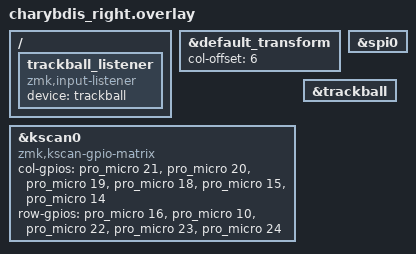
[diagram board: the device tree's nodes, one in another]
#include "charybdis.dtsi"
#include "charybdis_pmw3610.dtsi"

// The matrix transform is 6 columns over because the left half is 6 columns wide.
&default_transform {
	col-offset = <6>;
};

&kscan0 {
	compatible = "zmk,kscan-gpio-matrix";
	
	col-gpios
		= <&pro_micro 21 (GPIO_ACTIVE_HIGH | GPIO_PULL_DOWN)>//8
		, <&pro_micro 20 (GPIO_ACTIVE_HIGH | GPIO_PULL_DOWN)>//7
		, <&pro_micro 19 (GPIO_ACTIVE_HIGH | GPIO_PULL_DOWN)>//6
		, <&pro_micro 18 (GPIO_ACTIVE_HIGH | GPIO_PULL_DOWN)>//10
		, <&pro_micro 15 (GPIO_ACTIVE_HIGH | GPIO_PULL_DOWN)>//20
		, <&pro_micro 14 (GPIO_ACTIVE_HIGH | GPIO_PULL_DOWN)>//19
		;

	row-gpios
                = <&pro_micro 16  GPIO_ACTIVE_HIGH>//21
                , <&pro_micro 10  GPIO_ACTIVE_HIGH>//18
                , <&pro_micro 22  GPIO_ACTIVE_HIGH>//5
                , <&pro_micro 23  GPIO_ACTIVE_HIGH>//4
                , <&pro_micro 24 GPIO_ACTIVE_HIGH>//9
                ;
};

&spi0 {
    status = "okay";
};

&trackball {
    status = "okay";
};

// https://github.com/badjeff/zmk-pmw3610-driver
/ {
  trackball_listener {
    compatible = "zmk,input-listener";
    device = <&trackball>;
  };
};





